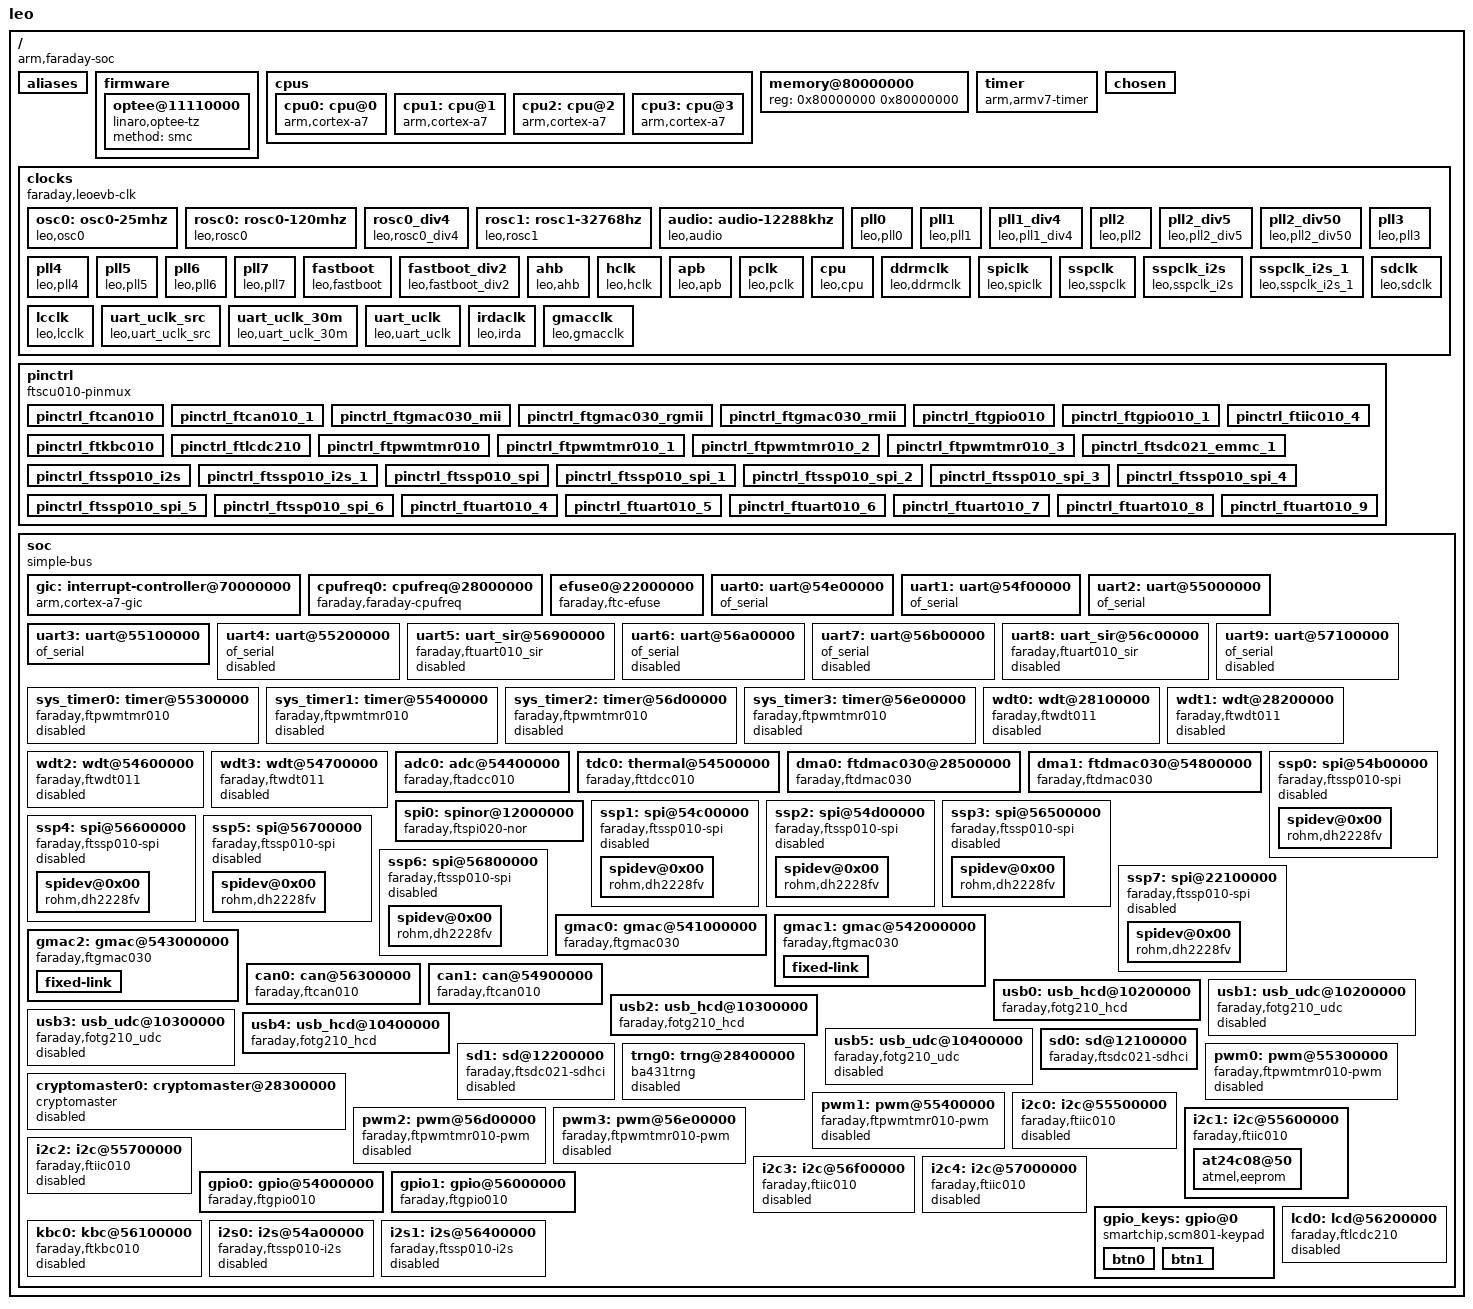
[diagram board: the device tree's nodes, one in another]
/*
 * Copyright (C) 2018 Faraday, Inc. (www.faraday-tech.com)
 *
 * This program is free software; you can redistribute it and/or modify
 * it under the terms of the GNU General Public License version 2 as
 * published by the Free Software Foundation.
 */
 
 /dts-v1/;
 
#include <dt-bindings/interrupt-controller/arm-gic.h>
#include <dt-bindings/input/input.h>
#include <dt-bindings/gpio/gpio.h>
#include <dt-bindings/pinctrl/pinctrl-leo.h>
#include <dt-bindings/thermal/thermal.h>
#include <dt-bindings/scu/scu-leo.h>
 
/ {
	model = "leo";
	compatible = "arm,faraday-soc";
	#address-cells = <1>;
	#size-cells = <1>;
	interrupt-parent = <&gic>;
	
	aliases {
		serial0 = &uart0;
		serial1 = &uart1;
		serial2 = &uart2;
		serial3 = &uart3;
		serial4 = &uart4;
		serial5 = &uart5;
		serial6 = &uart6;
		serial7 = &uart7;
		serial8 = &uart8;
		serial9 = &uart9;
		dmac030_0 = &dma0;
		dmac030_1 = &dma1;
	};
	
	firmware {
		optee@11110000{
		compatible = "linaro,optee-tz";
		method = "smc";
		};
	};
/*
	psci {
		compatible	= "arm,psci";
		method		= "smc";
		cpu_suspend	= <0x84000001>;
		cpu_off		= <0x84000002>;
		cpu_on		= <0x84000003>;
	};
*/
	cpus {
		#address-cells = <1>;
		#size-cells = <0>;
		
		cpu0: cpu@0 {
			compatible = "arm,cortex-a7";
			device_type = "cpu";
			clock-frequency = <800000000>;
			reg = <0x0>;
			/*enable-method = "psci";*/
		};
		cpu1: cpu@1 {
			compatible = "arm,cortex-a7";
			device_type = "cpu";
			clock-frequency = <800000000>;
			reg = <0x1>;
			/*enable-method = "psci";*/
		};
		cpu2: cpu@2 {
			compatible = "arm,cortex-a7";
			device_type = "cpu";
			clock-frequency = <800000000>;
			reg = <0x2>;
			/*enable-method = "psci";*/
		};
		cpu3: cpu@3 {
			compatible = "arm,cortex-a7";
			device_type = "cpu";
			clock-frequency = <800000000>;
			reg = <0x3>;
			/*enable-method = "psci";*/
		};
	};
	
	memory@80000000 {
		device_type = "memory";
		reg = <0x80000000 0x80000000>;
	};
	
	timer {
		compatible = "arm,armv7-timer";
		clock-frequency = <800000000>;  /* kernel default cpu frequency */
		interrupts = <GIC_PPI 13 (GIC_CPU_MASK_SIMPLE(4) | IRQ_TYPE_LEVEL_LOW)>,
		             <GIC_PPI 14 (GIC_CPU_MASK_SIMPLE(4) | IRQ_TYPE_LEVEL_LOW)>,
		             <GIC_PPI 11 (GIC_CPU_MASK_SIMPLE(4) | IRQ_TYPE_LEVEL_LOW)>,
		             <GIC_PPI 10 (GIC_CPU_MASK_SIMPLE(4) | IRQ_TYPE_LEVEL_LOW)>;
		arm,cpu-registers-not-fw-configured;
		clocks = <&cpu>;
		clock-names = "cpu";
		status = "okay";
	};
	
	chosen {
		bootargs = "mem=2048M console=ttyS0,115200 earlycon=uart8250,mmio32,0x54e00000 root=/dev/mmcblk0p2 rw init=/sbin/init rootfstype=ext4";
#if 0
                bootargs = "mem=2048M console=ttyS0,115200 earlycon=uart8250,mmio32,0x54e00000 root=/dev/mmcblk0p2 rw init=/linuxrc rootfstype=ext4";
               bootargs = "root=/dev/nfs   nfsroot=192.168.0.2:/home/niubin/rootfs,vers=3 ip=192.168.0.80:192.168.0.2:192.168.0.1:255.255.255.0::eth0:off init=/linuxrc mem=2048M console=ttyS0,115200 earlycon=uart8250,mmio32,0x54e00000";
#endif
	};
	
	clocks {
		compatible = "faraday,leoevb-clk";
		
		osc0: osc0-25mhz {
			#clock-cells = <0>;
			compatible = "leo,osc0";
			clock-frequency = <25000000>;
			clock-output-names = "osc0";
		};
		
		rosc0: rosc0-120mhz {
			#clock-cells = <0>;
			compatible = "leo,rosc0";
			clock-frequency = <120000000>;
			clock-output-names = "rosc0";
		};
		
		rosc0_div4: rosc0_div4 {
			#clock-cells = <0>;
			compatible = "leo,rosc0_div4";
			clock-mult = <1>;
			clock-div = <4>;
			clock-output-names = "rosc0_div4";
			clocks = <&rosc0>;
		};
		
		rosc1: rosc1-32768hz {
			#clock-cells = <0>;
			compatible = "leo,rosc1";
			clock-frequency = <32768>;
			clock-output-names = "rosc1";
		};
		
		audio: audio-12288khz {
			#clock-cells = <0>;
			compatible = "leo,audio";
			clock-frequency = <12288000>;
			clock-output-names = "audio";
		};
		
		pll0: pll0 {
			#clock-cells = <0>;
			compatible = "leo,pll0";
			clock-div = <1>;
			clock-output-names = "pll0";
			clocks = <&osc0>;
		};
		
		pll1: pll1 {
			#clock-cells = <0>;
			compatible = "leo,pll1";
			clock-div = <1>;
			clock-output-names = "pll1";
			clocks = <&osc0>;
		};
		
		
		pll1_div4: pll1_div4 {
			#clock-cells = <0>;
			compatible = "leo,pll1_div4";
			clock-mult = <1>;
			clock-div = <4>;
			clock-output-names = "pll1_div4";
			clocks = <&pll1>;
		};
		
		pll2: pll2 {
			#clock-cells = <0>;
			compatible = "leo,pll2";
			clock-div = <1>;
			clock-output-names = "pll2";
			clocks = <&osc0>;
		};
		
		pll2_div5: pll2_div5 {
			#clock-cells = <0>;
			compatible = "leo,pll2_div5";
			clock-mult = <1>;
			clock-div = <5>;
			clock-output-names = "pll2_div5";
			clocks = <&pll2>;
		};
		
		pll2_div50: pll2_div50 {
			#clock-cells = <0>;
			compatible = "leo,pll2_div50";
			clock-mult = <1>;
			clock-div = <50>;
			clock-output-names = "pll2_div50";
			clocks = <&pll2>;
		};
		
		pll3: pll3 {
			#clock-cells = <0>;
			compatible = "leo,pll3";
			clock-div = <16>;
			clock-output-names = "pll3";
			clocks = <&pll2_div50>;
		};
		
		pll4: pll4 {
			#clock-cells = <0>;
			compatible = "leo,pll4";
			clock-div = <2>;
			clock-output-names = "pll4";
			clocks = <&osc0>;
		};
		
		pll5: pll5 {
			#clock-cells = <0>;
			compatible = "leo,pll5";
			clock-div = <8>;
			clock-output-names = "pll5";
			clocks = <&pll2_div50>;
		};
		
		pll6: pll6 {
			#clock-cells = <0>;
			compatible = "leo,pll6";
			clock-div = <1>;
			clock-output-names = "pll6";
			clocks = <&osc0>;
		};
		
		pll7: pll7 {
			#clock-cells = <0>;
			compatible = "leo,pll7";
			clock-div = <2>;
			clock-output-names = "pll7";
			clocks = <&osc0>;
		};
		
		fastboot: fastboot {
			#clock-cells = <0>;
			compatible = "leo,fastboot";
			clock-output-names = "fastboot";
			clocks = <&rosc0>, <&osc0>;
		};
		
		fastboot_div2: fastboot_div2 {
			#clock-cells = <0>;
			compatible = "leo,fastboot_div2";
			clock-output-names = "fastboot_div2";
			clock-mult = <1>;
			clock-div = <2>;
			clocks = <&fastboot>;
		};
		
		ahb: ahb {
			#clock-cells = <0>;
			compatible = "leo,ahb";
			clock-mult = <1>;
			clock-div = <4>;
			clock-output-names = "AHB";
			clocks = <&pll1>, <&fastboot_div2>;
		};
		
		hclk: hclk {
			#clock-cells = <0>;
			compatible = "leo,hclk";
			clock-mult = <1>;
			clock-div = <4>;
			clock-output-names = "hclk";
			clocks = <&pll1>, <&fastboot_div2>;
		};
		
		apb: apb {
			#clock-cells = <0>;
			compatible = "leo,apb";
			clock-mult = <1>;
			clock-div = <8>;
			clock-output-names = "APB";
			clocks = <&fastboot>, <&pll6>;
		};
		
		pclk: pclk {
			#clock-cells = <0>;
			compatible = "leo,pclk";
			clock-mult = <1>;
			clock-div = <8>;
			clock-output-names = "pclk";
			clocks = <&fastboot>, <&pll6>;
		};
		
		cpu: cpu {
			#clock-cells = <0>;
			compatible = "leo,cpu";
			mux-reg = <0x30>;
			mux-shift = <6>;
			mux-mask = <1>;
			div-reg = <0x30>;
			div-shift = <4>;
			div-width = <3>;
			clock-output-names = "cpu";
			clocks = <&pll0>, <&fastboot>;
		};
		
		ddrmclk: ddrmclk {
			#clock-cells = <0>;
			compatible = "leo,ddrmclk";
			clock-mult = <1>;
			clock-div = <1>;
			clock-output-names = "ddrmclk";
			clocks = <&pll4>;
		};
		
		spiclk: spiclk {
			#clock-cells = <0>;
			compatible = "leo,spiclk";
			clock-output-names = "spiclk";
			clocks = <&fastboot>, <&pll1>;
		};
		
		sspclk: sspclk {
			#clock-cells = <0>;
			compatible = "leo,sspclk";
			clock-output-names = "sspclk";
			clocks = <&fastboot>, <&pll1>;
		};
		
		sspclk_i2s: sspclk_i2s {
			#clock-cells = <0>;
			compatible = "leo,sspclk_i2s";
			clock-output-names = "sspclk_i2s";
			clocks = <&sspclk>, <&audio>;
		};
		
		sspclk_i2s_1: sspclk_i2s_1 {
			#clock-cells = <0>;
			compatible = "leo,sspclk_i2s_1";
			clock-output-names = "sspclk_i2s_1";
			clocks = <&sspclk>, <&audio>;
		};
		
		sdclk: sdclk {
			#clock-cells = <0>;
			compatible = "leo,sdclk";
			clock-output-names = "sdclk";
			clocks = <&fastboot_div2>, <&pll7>;
		};
		
		lcclk: lcclk {
			#clock-cells = <0>;
			compatible = "leo,lcclk";
			clock-output-names = "lcclk";
			clock-mult = <1>;
			clock-div = <2>;
			clocks = <&pll5>;
		};
		
		uart_uclk_src: uart_uclk_src {
			#clock-cells = <0>;
			compatible = "leo,uart_uclk_src";
			clock-mult = <100>;
			clock-div = <425>;
			clock-output-names = "uart_uclk_src";
			clocks = <&pll1_div4>;
		};
		
		uart_uclk_30m: uart_uclk_30m {
			#clock-cells = <0>;
			compatible = "leo,uart_uclk_30m";
			clock-mult = <1>;
			clock-output-names = "uart_uclk_30m";
			clocks = <&rosc0_div4>, <&uart_uclk_src>;
		};
		
		uart_uclk: uart_uclk {
			#clock-cells = <0>;
			compatible = "leo,uart_uclk";
			clock-mult = <1>;
			clock-output-names = "uart_uclk";
			clocks = <&uart_uclk_30m>, <&pll2_div5>;
		};
		
		irdaclk: irdaclk {
			#clock-cells = <0>;
			compatible = "leo,irda";
			clock-mult = <1>;
			clock-div = <5>;
			clock-output-names = "irda";
			clocks = <&pll2>;
		};
		
		gmacclk: gmacclk {
			#clock-cells = <0>;
			compatible = "leo,gmacclk";
			clock-mult = <1>;
			clock-div = <20>;
			clock-output-names = "gmacclk";
			clocks = <&pll1>;
		};
	};


	pinctrl {
		compatible = "ftscu010-pinmux", "pinctrl-leo";
		reg = <0x28000000 0xA000>;

		scu010,modex = <
			LEO_Mode_X_GPIO0_26
			LEO_Mode_X_GPIO0_25
#if 0
			LEO_Mode_X_GPIO0_24   
#endif 
			LEO_Mode_X_GPIO0_23
			LEO_Mode_X_GPIO0_22
#if 0
			LEO_Mode_X_GPIO0_21
#endif
			LEO_Mode_X_GPIO0_20
			LEO_Mode_X_GPIO0_19
#if 0
			LEO_Mode_X_GPIO0_18
			LEO_Mode_X_GPIO0_17
#endif
			LEO_Mode_X_GPIO0_3
			LEO_Mode_X_GPIO0_2
		>;
		
		pinctrl_ftcan010: pinctrl_ftcan010 {
			scu010,function = <LEO_MUX_FTCAN010>;
			scu010,pins = <
			#if 0
				LEO_PIN_X_LC_PCLK
				LEO_PIN_X_LC_VS
			#elif 0
				LEO_PIN_X_RMII0_TXD_0
				LEO_PIN_X_RMII0_TXD_1
			#else
				LEO_PIN_X_UART5_RX
				LEO_PIN_X_UART5_TX
			#endif
			>;
		};
		
		pinctrl_ftcan010_1: pinctrl_ftcan010_1 {
			scu010,function = <LEO_MUX_FTCAN010_1>;
			scu010,pins = <
			#if 0
				LEO_PIN_X_LC_DE
				LEO_PIN_X_LC_HS
			#elif 0
				LEO_PIN_X_RMII0_RX_CRSDV
				LEO_PIN_X_RMII0_TX_EN
			#else
				LEO_PIN_X_UART8_RX
				LEO_PIN_X_UART8_TX
			#endif
			>;
		};
		
		pinctrl_ftgmac030_mii: pinctrl_ftgmac030_mii {
			scu010,function = <LEO_MUX_FTGMAC030_MII>;
			scu010,pins = <
				LEO_PIN_X_MII_COL
				LEO_PIN_X_MII_CRS
				LEO_PIN_X_MII_MDC
				LEO_PIN_X_MII_MDIO
				LEO_PIN_X_MII_RXD_0
				LEO_PIN_X_MII_RXD_1
				LEO_PIN_X_MII_RXD_2
				LEO_PIN_X_MII_RXD_3
				LEO_PIN_X_MII_RX_CK
				LEO_PIN_X_MII_RX_DV
				LEO_PIN_X_MII_RX_ER
				LEO_PIN_X_MII_TXD_0
				LEO_PIN_X_MII_TXD_1
				LEO_PIN_X_MII_TXD_2
				LEO_PIN_X_MII_TXD_3
				LEO_PIN_X_MII_TX_CK
				LEO_PIN_X_MII_TX_EN
				LEO_PIN_X_MII_TX_ER
			>;
		};
		
		pinctrl_ftgmac030_rgmii: pinctrl_ftgmac030_rgmii {
			scu010,function = <LEO_MUX_FTGMAC030_RGMII>;
			scu010,pins = <
				LEO_PIN_X_RGMII_GTX_CK
				LEO_PIN_X_RGMII_MDC
				LEO_PIN_X_RGMII_MDIO
				LEO_PIN_X_RGMII_RXCTL
				LEO_PIN_X_RGMII_RXD_0
				LEO_PIN_X_RGMII_RXD_1
				LEO_PIN_X_RGMII_RXD_2
				LEO_PIN_X_RGMII_RXD_3
				LEO_PIN_X_RGMII_RX_CK
				LEO_PIN_X_RGMII_TXCTL
				LEO_PIN_X_RGMII_TXD_0
				LEO_PIN_X_RGMII_TXD_1
				LEO_PIN_X_RGMII_TXD_2
				LEO_PIN_X_RGMII_TXD_3
			>;
		};
		
		pinctrl_ftgmac030_rmii: pinctrl_ftgmac030_rmii {
			scu010,function = <LEO_MUX_FTGMAC030_RMII>;
			scu010,pins = <
				LEO_PIN_X_RMII0_MDC
				LEO_PIN_X_RMII0_MDIO
				LEO_PIN_X_RMII0_REF_CLK
				LEO_PIN_X_RMII0_RXD_0
				LEO_PIN_X_RMII0_RXD_1
				LEO_PIN_X_RMII0_RX_CRSDV
				LEO_PIN_X_RMII0_RX_ER
				LEO_PIN_X_RMII0_TXD_0
				LEO_PIN_X_RMII0_TXD_1
				LEO_PIN_X_RMII0_TX_EN
			>;
		};
		
		pinctrl_ftgpio010: pinctrl_ftgpio010 {
			scu010,schmitt-trigger;
			scu010,function = <LEO_MUX_FTGPIO010>;
			scu010,pins = <
				LEO_PIN_X_LC_PCLK        //GPIO0[0] - Mode5 / Mode7
				//LEO_PIN_X_UART5_TX       //GPIO0[0] - Mode3 / GPIO0[2] - ModeX
				//LEO_PIN_X_UART5_RX       //GPIO0[1] - Mode3 / GPIO0[3] - ModeX   
				//LEO_PIN_X_LC_VS          //GPIO0[1] - Mode5 / Mode7
				//LEO_PIN_X_LC_HS          //GPIO0[2] - Mode5 / Mode7
				//LEO_PIN_X_LC_DE          //GPIO0[3] - Mode5 / Mode7
				//LEO_PIN_X_LC_DATA_0      //GPIO0[4] - Mode5 / Mode7
				//LEO_PIN_X_LC_DATA_1      //GPIO0[5] - Mode5 / Mode7
				LEO_PIN_X_LC_DATA_2      //GPIO0[6] - Mode5 / Mode7
				//LEO_PIN_X_LC_DATA_3      //GPIO0[7] - Mode5 / Mode7
				//LEO_PIN_X_LC_DATA_4      //GPIO0[8] - Mode5 / Mode7
				//LEO_PIN_X_LC_DATA_5      //GPIO0[9] - Mode5 / Mode7 / GPIO0[21] - ModeX
				//LEO_PIN_X_UART8_TX       //GPIO0[9] - Mode3  
				//LEO_PIN_X_MII_RX_CK      //GPIO0[9] - Mode1 / Mode3 / Mode4
				//LEO_PIN_X_LC_DATA_6      //GPIO0[10] - Mode5 / Mode7 / GPIO0[17] - ModeX
				//LEO_PIN_X_MII_RXD_2      //GPIO0[10] - Mode1 / Mode3 / Mode4
				//LEO_PIN_X_UART8_RX       //GPIO0[10] - Mode3
				//LEO_PIN_X_MII_RXD_3      //GPIO0[11] - Mode1 / Mode3 / Mode4) 
				//LEO_PIN_X_UART8_RX_h     //GPIO0[11] - Mode3 
				//LEO_PIN_X_LC_DATA_7      //GPIO0[11] - Mode5 / Mode7
				//LEO_PIN_X_LC_DATA_8      //GPIO0[12] - Mode5 / Mode7
				//LEO_PIN_X_MII_TX_CK      //GPIO0[12] - Mode1 / Mode3 /Mode4 
				//LEO_PIN_X_LC_DATA_9      //GPIO0[13] - Mode5 / Mode7
				//LEO_PIN_X_MII_TX_ER      //GPIO0[13] - Mode1 / Mode3 / Mode4
				//LEO_PIN_X_LC_DATA_10     //GPIO0[14] - Mode5 / Mode7
				//LEO_PIN_X_MII_TXD_2      //GPIO0[14] - Mode1 / Mode3 / Mode4
				//LEO_PIN_X_MII_TXD_3      //GPIO0[15] - Mode1 / Mode3 / Mode4
				//LEO_PIN_X_LC_DATA_11     //GPIO0[15] - Mode5 / Mode7
				//LEO_PIN_X_LC_DATA_12     //GPIO0[16] - Mode5 / Mode7
				//LEO_PIN_X_MII_CRS        //GPIO0[16] - Mode1 / Mode3 / Mode4
				//LEO_PIN_X_LC_DATA_13     //GPIO0[17] - Mode5 / Mode7
				//LEO_PIN_X_MII_COL        //GPIO0[17] - Mode1 / Mode3 / Mode4
				//LEO_PIN_X_LC_DATA_14     //GPIO0[18] - Mode5 / Mode7
				//LEO_PIN_X_I2S0_TXD       //GPIO0[18] - ModeX 
				//LEO_PIN_X_LC_DATA_15     //GPIO0[19] - Mode5 / Mode7
				//LEO_PIN_X_UART2_NRTS     //GPIO0[19] - ModeX 
				//LEO_PIN_X_LC_DATA_16     //GPIO0[20] - Mode5 / Mode7
				//LEO_PIN_X_UART2_NCTS     //GPIO0[20] - ModeX
				//LEO_PIN_X_LC_DATA_17     //GPIO0[21] - Mode5 / Mode7
				//LEO_PIN_X_LC_DATA_18     //GPIO0[22] - Mode5 / Mode7
				//LEO_PIN_X_I2S0_RXD       //GPIO0[22] - ModeX /GPIO1[12] - Mode2
				//LEO_PIN_X_I2S0_SCLK      //GPIO0[23] - ModeX /GPIO1[13] - Mode2
				//LEO_PIN_X_LC_DATA_19     //GPIO0[23] - Mode5 / Mode7
				//LEO_PIN_X_LC_DATA_20     //GPIO0[24] - Mode5 / Mode7
				//LEO_PIN_X_MII_TX_EN      //GPIO0[24] - Mode7
				//LEO_PIN_X_LC_DATA_21     //GPIO0[25] - Mode5 / Mode7
				//LEO_PIN_X_I2S0_FS        //GPIO0[25] - ModeX
				//LEO_PIN_X_RMII0_RXD_1    //GPIO0[26] - ModeX 
				//LEO_PIN_X_LC_DATA_22     //GPIO0[26] - Mode5 / Mode7
				LEO_PIN_X_LC_DATA_23     //GPIO0[27] - Mode5 / Mode7
				LEO_PIN_X_I2S_MCLK       //GPIO0[28] - Mode2 / Mode6 / Mode7
				//LEO_PIN_X_MII_MDC        //GPIO0[31] - Mode7
				LEO_PIN_X_LC_DE         //gpio0[3]
			>;
		};
		
		pinctrl_ftgpio010_1: pinctrl_ftgpio010_1 {
			scu010,schmitt-trigger;
			scu010,function = <LEO_MUX_FTGPIO010_1>;
			scu010,pins = <
				//LEO_PIN_X_MII_MDIO       //GPIO1[0] - Mode7 / GPIO1[26] - Mode1 / Mode3
				//LEO_PIN_X_EMMC1_D7       //GPIO1[0] - Mode1 / Mode3 / Mode4 / Mode5 / Mode7
				//LEO_PIN_X_MII_RX_CK      //GPIO1[1] - Mode7
				//LEO_PIN_X_EMMC1_D6       //GPIO1[1] - Mode1 / Mode3 / Mode4 / Mode5 / Mode7
				//LEO_PIN_X_EMMC1_D5       //GPIO1[2] - Mode1 / Mode3 / Mode4 /Mode5 / Mode7
				//LEO_PIN_X_MII_RXD_2      //GPIO1[2] - Mode7
				//LEO_PIN_X_MII_RXD_3      //GPIO1[3] - Mode7
				//LEO_PIN_X_EMMC1_D4       //GPIO1[3] - Mode1 / Mode3 / Mode4 / Mode5 / Mode7
				//LEO_PIN_X_EMMC1_D3       //GPIO1[4] - Mode1 / Mode3 / Mode4 / Mode5 / Mode7
				//LEO_PIN_X_MII_TX_CK      //GPIO1[4] - Mode7
				//LEO_PIN_X_RMII0_TXD_0    //GPIO1[5] - Mode7
				//LEO_PIN_X_EMMC1_D2       //GPIO1[5] - Mode1 / Mode3 / Mode4 / Mode5 / Mode7
				//LEO_PIN_X_EMMC1_D1       //GPIO1[6] - Mode1 / Mode3 / Mode4 / Mode5 / Mode7
				//LEO_PIN_X_RMII0_TXD_1    //GPIO1[6] - Mode7
				//LEO_PIN_X_EMMC1_D0       //GPIO1[7] - Mode1 / Mode3 / Mode4 / Mode5 / Mode7
				//LEO_PIN_X_RMII0_TX_EN    //GPIO1[7] - Mode7
				//LEO_PIN_X_EMMC1_RSTN     //GPIO1[8] - Mode1 / Mode3 / Mode4 / Mode5 / Mode7
				//LEO_PIN_X_RMII0_RX_CRSDV //GPIO1[8] - Mode7
				//LEO_PIN_X_EMMC1_CMD      //GPIO1[9] - Mode1 / Mode3 / Mode4 / Mode5 / Mode7
				//LEO_PIN_X_RMII0_RX_ER    //GPIO1[9] - Mode7
				//LEO_PIN_X_RMII0_RXD_0    //GPIO1[10] - Mode7
				//LEO_PIN_X_RMII0_RXD_1    //GPIO1[11] - Mode3 / Mode5 / Mode7
				//LEO_PIN_X_I2S0_FS        //GPIO1[11] - Mode2
				//LEO_PIN_X_I2S0_RXD       //GPIO1[12] - Mode2
				//LEO_PIN_X_RGMII_GTX_CK   //GPIO1[12] - Mode3 / Mode5 / Mode7
				//LEO_PIN_X_UART8_TX       //GPIO1[12] - Mode6
				//LEO_PIN_X_I2S0_SCLK      //GPIO1[13] - Mode2
				//LEO_PIN_X_UART8_RX       //GPIO1[13] - Mode6
				//LEO_PIN_X_RGMII_MDC      //GPIO1[13] - Mode3 / Mode5 / Mode7 / GPIO1[25] - Mode2
				//LEO_PIN_X_UART8_RX_h     //GPIO1[14] - Mode6
				//LEO_PIN_X_RMII0_MDIO      //GPIO1[14] - Mode3 / Mode5 / Mode7
				//LEO_PIN_X_MII_TX_ER      //GPIO1[15] - Mode7
				//LEO_PIN_X_MII_TXD_2      //GPIO1[16] - Mode7
				//LEO_PIN_X_MII_TXD_3      //GPIO1[17] - Mode7
				//LEO_PIN_X_MII_CRS        //GPIO1[18] - Mode7
				//LEO_PIN_X_MII_COL        //GPIO1[19] - Mode7
				//LEO_PIN_X_MII_TXD_0      //GPIO1[23] - Mode7
				//LEO_PIN_X_RGMII_MDC      //GPIO1[23] - Mode1 / Mode2 / Mode4
				//LEO_PIN_X_RGMII_MDIO     //GPIO1[24] - Mode1 / Mode2 / Mode4
				//LEO_PIN_X_MII_TXD_1      //GPIO1[24] - Mode7
				//LEO_PIN_X_MII_TX_EN      //GPIO1[25] - ModeX
				//LEO_PIN_X_MII_MDC        //GPIO1[25] - Mode1 / Mode3
				//LEO_PIN_X_RMII0_MDC      //GPIO1[25] - Mode2 / GPIO1[13] - Mode3 / Mode5 / Mode7
				//LEO_PIN_X_MII_RX_DV      //GPIO1[26] - Mode7
				//LEO_PIN_X_MII_RX_ER      //GPIO1[27] - Mode7
				//LEO_PIN_X_MII_RXD_0      //GPIO1[28] - Mode7
				//LEO_PIN_X_MII_RXD_1      //GPIO1[29] - Mode7
			>;
		};
		
		pinctrl_ftiic010_4: pinctrl_ftiic010_4 {
			scu010,function = <LEO_MUX_FTIIC010_4>;
			scu010,pins = <
			#if 1
				LEO_PIN_X_EMMC1_D2
				LEO_PIN_X_EMMC1_D3
			#else
				LEO_PIN_X_LC_DATA_8
				LEO_PIN_X_LC_DATA_9
			#endif
			>;
		};
		
		pinctrl_ftkbc010: pinctrl_ftkbc010 {
			scu010,function = <LEO_MUX_FTKBC010>;
			scu010,pins = <
			#if 0
				LEO_PIN_X_I2S0_FS			//CODE_X0
				LEO_PIN_X_I2S0_RXD 			//CODE_X1
				LEO_PIN_X_I2S0_SCLK			//CODE_X2
				LEO_PIN_X_I2S0_TXD 			//CODE_X3
			#else
				LEO_PIN_X_RGMII_RX_CK		//CODE_X0
				LEO_PIN_X_RGMII_RXD_0		//CODE_X1
				LEO_PIN_X_RGMII_RXD_1		//CODE_X2
				LEO_PIN_X_RGMII_RXD_2		//CODE_X3
			#endif
				LEO_PIN_X_RGMII_RXD_3		//CODE_X4
				LEO_PIN_X_RGMII_RXCTL		//CODE_X5
				LEO_PIN_X_RGMII_GTX_CK 		//CODE_X6
				LEO_PIN_X_RGMII_TXCTL		//CODE_X7

			#if 0
				LEO_PIN_X_MII_TXD_0			//CODE_Y0
				LEO_PIN_X_MII_TXD_1			//CODE_Y1
				LEO_PIN_X_MII_TX_EN			//CODE_Y2
				LEO_PIN_X_MII_RX_DV			//CODE_Y3
				LEO_PIN_X_MII_RX_ER			//CODE_Y4
				LEO_PIN_X_MII_RXD_0			//CODE_Y5
				LEO_PIN_X_MII_RXD_1			//CODE_Y6
			#elif 1
				LEO_PIN_X_RMII0_TXD_0		//CODE_Y0
				LEO_PIN_X_RMII0_TXD_1		//CODE_Y1
				LEO_PIN_X_RMII0_TX_EN		//CODE_Y2
				LEO_PIN_X_RMII0_RX_CRSDV	//CODE_Y3
				LEO_PIN_X_RMII0_RX_ER		//CODE_Y4
				LEO_PIN_X_RMII0_RXD_0		//CODE_Y5
				LEO_PIN_X_RMII0_RXD_1		//CODE_Y6
			#else
				LEO_PIN_X_UART5_TX 			//CODE_Y0
				LEO_PIN_X_UART5_RX 			//CODE_Y1
				LEO_PIN_X_UART5_RX_h		//CODE_Y2
				LEO_PIN_X_UART6_TX 			//CODE_Y3
				LEO_PIN_X_UART6_RX 			//CODE_Y4
				LEO_PIN_X_UART9_TX 			//CODE_Y5
				LEO_PIN_X_UART7_TX 			//CODE_Y6
			#endif

			#if 1
				LEO_PIN_X_RMII0_REF_CLK		//CODE_Y7
			#else
				LEO_PIN_X_UART7_RX	 		//CODE_Y7
			#endif
			>;
		};
		
		pinctrl_ftlcdc210: pinctrl_ftlcdc210 {
			scu010,function = <LEO_MUX_FTLCDC210>;
			scu010,pins = <
				LEO_PIN_X_LC_DATA_0
				LEO_PIN_X_LC_DATA_1
				LEO_PIN_X_LC_DATA_10
				LEO_PIN_X_LC_DATA_11
				LEO_PIN_X_LC_DATA_12
				LEO_PIN_X_LC_DATA_13
				LEO_PIN_X_LC_DATA_14
				LEO_PIN_X_LC_DATA_15
				LEO_PIN_X_LC_DATA_16
				LEO_PIN_X_LC_DATA_17
				LEO_PIN_X_LC_DATA_18
				LEO_PIN_X_LC_DATA_19
				LEO_PIN_X_LC_DATA_2
				LEO_PIN_X_LC_DATA_20
				LEO_PIN_X_LC_DATA_21
				LEO_PIN_X_LC_DATA_22
				LEO_PIN_X_LC_DATA_23
				LEO_PIN_X_LC_DATA_3
				LEO_PIN_X_LC_DATA_4
				LEO_PIN_X_LC_DATA_5
				LEO_PIN_X_LC_DATA_6
				LEO_PIN_X_LC_DATA_7
				LEO_PIN_X_LC_DATA_8
				LEO_PIN_X_LC_DATA_9
				LEO_PIN_X_LC_DE
				LEO_PIN_X_LC_HS
				LEO_PIN_X_LC_PCLK
				LEO_PIN_X_LC_VS
			>;
		};
		
		pinctrl_ftpwmtmr010: pinctrl_ftpwmtmr010 {
			scu010,function = <LEO_MUX_FTPWMTMR010>;
			scu010,pins = <
				LEO_PIN_X_EMMC1_CLK
				LEO_PIN_X_I2S0_FS
				LEO_PIN_X_I2S0_RXD
				LEO_PIN_X_I2S0_SCLK
				LEO_PIN_X_LC_DATA_0
				LEO_PIN_X_LC_DATA_1
				LEO_PIN_X_LC_DATA_2
				LEO_PIN_X_LC_DATA_3
				LEO_PIN_X_MII_MDC
				LEO_PIN_X_MII_MDIO
				LEO_PIN_X_RGMII_TXD_0
				LEO_PIN_X_RGMII_TXD_1
				LEO_PIN_X_RMII0_MDIO
				LEO_PIN_X_UART5_RX_h
				LEO_PIN_X_UART8_RX_h
			>;
		};
		
		pinctrl_ftpwmtmr010_1: pinctrl_ftpwmtmr010_1 {
			scu010,function = <LEO_MUX_FTPWMTMR010_1>;
			scu010,pins = <
				LEO_PIN_X_I2S0_TXD
				LEO_PIN_X_RGMII_MDC
				//LEO_PIN_X_RGMII_MDIO
				LEO_PIN_X_RGMII_TXD_2
				LEO_PIN_X_RGMII_TXD_3
			>;
		};
		
		pinctrl_ftpwmtmr010_2: pinctrl_ftpwmtmr010_2 {
			scu010,function = <LEO_MUX_FTPWMTMR010_2>;
			scu010,pins = <
				LEO_PIN_X_RMII0_RX_CRSDV
				LEO_PIN_X_RMII0_TXD_0
				LEO_PIN_X_RMII0_TXD_1
				LEO_PIN_X_RMII0_TX_EN
			>;
		};
		
		pinctrl_ftpwmtmr010_3: pinctrl_ftpwmtmr010_3 {
			scu010,function = <LEO_MUX_FTPWMTMR010_3>;
			scu010,pins = <
				LEO_PIN_X_RMII0_RXD_0
				LEO_PIN_X_RMII0_RX_ER
			>;
		};
		
		pinctrl_ftsdc021_emmc_1: pinctrl_ftsdc021_emmc_1 {
			scu010,function = <LEO_MUX_FTSDC021_EMMC_1>;
			scu010,pins = <
				LEO_PIN_X_EMMC1_CLK
				LEO_PIN_X_EMMC1_CMD
				LEO_PIN_X_EMMC1_D0
				LEO_PIN_X_EMMC1_D1
				LEO_PIN_X_EMMC1_D2
				LEO_PIN_X_EMMC1_D3
				LEO_PIN_X_EMMC1_D4
				LEO_PIN_X_EMMC1_D5
				LEO_PIN_X_EMMC1_D6
				LEO_PIN_X_EMMC1_D7
				LEO_PIN_X_EMMC1_RSTN
			>;
		};
		
		pinctrl_ftssp010_i2s: pinctrl_ftssp010_i2s {
			scu010,function = <LEO_MUX_FTSSP010_I2S>;
			scu010,pins = <
				LEO_PIN_X_I2S_MCLK
				LEO_PIN_X_I2S0_FS
				LEO_PIN_X_I2S0_RXD
				LEO_PIN_X_I2S0_SCLK
				LEO_PIN_X_I2S0_TXD
			>;
		};
		
		pinctrl_ftssp010_i2s_1: pinctrl_ftssp010_i2s_1 {
			scu010,function = <LEO_MUX_FTSSP010_I2S_1>;
			scu010,pins = <
				LEO_PIN_X_I2S_MCLK
			#if 1
				LEO_PIN_X_EMMC1_D4
				LEO_PIN_X_EMMC1_D5
				LEO_PIN_X_EMMC1_D6
				LEO_PIN_X_EMMC1_D7
			#else
				LEO_PIN_X_LC_DATA_4
				LEO_PIN_X_LC_DATA_5
				LEO_PIN_X_LC_DATA_6
				LEO_PIN_X_LC_DATA_7
			#endif
			>;
		};
		
		pinctrl_ftssp010_spi: pinctrl_ftssp010_spi {
			scu010,function = <LEO_MUX_FTSSP010_SPI>;
			scu010,pins = <
				LEO_PIN_X_LC_DATA_12
				LEO_PIN_X_LC_DATA_13
				LEO_PIN_X_SPI_DCX1
			>;
		};
		
		pinctrl_ftssp010_spi_1: pinctrl_ftssp010_spi_1 {
			scu010,function = <LEO_MUX_FTSSP010_SPI_1>;
			scu010,pins = <
				LEO_PIN_X_LC_DATA_14
				LEO_PIN_X_LC_DATA_15
				LEO_PIN_X_SPI_DCX2
			>;
		};
		
		pinctrl_ftssp010_spi_2: pinctrl_ftssp010_spi_2 {
			scu010,function = <LEO_MUX_FTSSP010_SPI_2>;
			scu010,pins = <
				LEO_PIN_X_LC_DATA_16
				LEO_PIN_X_LC_DATA_17
				LEO_PIN_X_SPI_DCX1
			>;
		};
		
		pinctrl_ftssp010_spi_3: pinctrl_ftssp010_spi_3 {
			scu010,function = <LEO_MUX_FTSSP010_SPI_3>;
			scu010,pins = <
				LEO_PIN_X_LC_DATA_18
				LEO_PIN_X_LC_DATA_19
				LEO_PIN_X_SPI_DCX2
			>;
		};
		
		pinctrl_ftssp010_spi_4: pinctrl_ftssp010_spi_4 {
			scu010,function = <LEO_MUX_FTSSP010_SPI_4>;
			scu010,pins = <
				LEO_PIN_X_LC_DATA_20
				LEO_PIN_X_LC_DATA_21
				LEO_PIN_X_LC_DATA_22
				LEO_PIN_X_LC_DATA_23
				LEO_PIN_X_SPI_DCX1
			>;
		};
		
		pinctrl_ftssp010_spi_5: pinctrl_ftssp010_spi_5 {
			scu010,function = <LEO_MUX_FTSSP010_SPI_5>;
			scu010,pins = <
				LEO_PIN_X_SPI_DCX2
			>;
		};
		
		pinctrl_ftssp010_spi_6: pinctrl_ftssp010_spi_6 {
			scu010,function = <LEO_MUX_FTSSP010_SPI_6>;
			scu010,pins = <
				LEO_PIN_X_EMMC1_CMD
				LEO_PIN_X_EMMC1_RSTN
				LEO_PIN_X_SPI_DCX1
			>;
		};
		
		pinctrl_ftuart010_4: pinctrl_ftuart010_4 {
			scu010,function = <LEO_MUX_FTUART010_4>;
			scu010,pins = <
				LEO_PIN_X_EMMC1_D0
				LEO_PIN_X_EMMC1_D1
				LEO_PIN_X_LC_DATA_10
				LEO_PIN_X_LC_DATA_11
			>;
		};
		
		pinctrl_ftuart010_5: pinctrl_ftuart010_5 {
			scu010,function = <LEO_MUX_FTUART010_5>;
			scu010,pins = <
				LEO_PIN_X_UART5_RX
				LEO_PIN_X_UART5_RX_h
				LEO_PIN_X_UART5_TX
			>;
		};
		
		pinctrl_ftuart010_6: pinctrl_ftuart010_6 {
			scu010,function = <LEO_MUX_FTUART010_6>;
			scu010,pins = <
				LEO_PIN_X_UART6_RX
				LEO_PIN_X_UART6_TX
			>;
		};
		
		pinctrl_ftuart010_7: pinctrl_ftuart010_7 {
			scu010,function = <LEO_MUX_FTUART010_7>;
			scu010,pins = <
				LEO_PIN_X_UART7_RX
				LEO_PIN_X_UART7_TX
			>;
		};
		
		pinctrl_ftuart010_8: pinctrl_ftuart010_8 {
			scu010,function = <LEO_MUX_FTUART010_8>;
			scu010,pins = <
				LEO_PIN_X_UART8_RX
				LEO_PIN_X_UART8_RX_h
				LEO_PIN_X_UART8_TX
			>;
		};
		
		pinctrl_ftuart010_9: pinctrl_ftuart010_9 {
			scu010,function = <LEO_MUX_FTUART010_9>;
			scu010,pins = <
				LEO_PIN_X_UART9_RX
				LEO_PIN_X_UART9_TX
			>;
		};
	};
	
	soc {
		#address-cells = <1>;
		#size-cells = <1>;
		compatible = "simple-bus";
		ranges;
		
		gic: interrupt-controller@70000000 {
			compatible = "arm,cortex-a7-gic";
			interrupt-controller;
			#interrupt-cells = <3>;
			reg = <0x70001000 0x1000>,
			      <0x70002000 0x2000>,
			      <0x70004000 0x2000>,
			      <0x70006000 0x2000>;
		};

		cpufreq0: cpufreq@28000000 {
			compatible = "faraday,faraday-cpufreq";
			interrupt-parent = <&gic>;
			reg = <0x28000000 0xA000>,
			      <0x28900000 0x1000>,
			      <0x54e00000 0x1000>;
			reg-names = "sysc", "ddrc", "uart";
			interrupts = <GIC_SPI 0 IRQ_TYPE_LEVEL_HIGH>;
			clocks = <&cpu>;
			clock-names = "cpu";
			operating-points = <
				/* KHz	  uV */
				100000 1100000
				200000 1100000
				400000 1100000
				800000 1100000
			>;
			status = "okay";
		};

		efuse0@22000000 {
	                compatible = "faraday,ftc-efuse";
        	        interrupt-parent = <&gic>;
                	reg = <0x22000000 0x10000>;
	                efuse-size = <512>;   /* 4096 bits */
        	        status = "okay";
        	};

		uart0: uart@54e00000 {
			compatible = "of_serial", "ns16550a";
			interrupt-parent = <&gic>;
			clock-frequency = <58823529>;
			reg = <0x54e00000 0x1000>;
			reg-offset = <0>;
			reg-shift = <2>;
			reg-io-width = <4>;
			no-loopback-test;
			interrupts = <GIC_SPI 45 IRQ_TYPE_LEVEL_HIGH>;
			serial = <0>;
			status = "okay";
		};
		
		uart1: uart@54f00000 {
			compatible = "of_serial", "ns16550a";
			interrupt-parent = <&gic>;
			clock-frequency = <58823529>;
			reg = <0x54f00000 0x1000>;
			reg-offset = <0>;
			reg-shift = <2>;
			reg-io-width = <4>;
			no-loopback-test;
			interrupts = <GIC_SPI 47 IRQ_TYPE_LEVEL_HIGH>;
			serial = <1>;
			status = "okay";
		};
		
		uart2: uart@55000000 {
			compatible = "of_serial", "ns16550a";
			interrupt-parent = <&gic>;
			clock-frequency = <58823529>;
			reg = <0x55000000 0x1000>;
			reg-offset = <0>;
			reg-shift = <2>;
			reg-io-width = <4>;
			no-loopback-test;
			interrupts = <GIC_SPI 49 IRQ_TYPE_LEVEL_HIGH>;
			serial = <2>;
			rs485-dir-gpios = <19>;
			status = "okay";
		};
		
		uart3: uart@55100000 {
			compatible = "of_serial", "ns16550a";
			interrupt-parent = <&gic>;
			clock-frequency = <58823529>;
			reg = <0x55100000 0x1000>;
			reg-offset = <0>;
			reg-shift = <2>;
			reg-io-width = <4>;
			no-loopback-test;
			interrupts = <GIC_SPI 51 IRQ_TYPE_LEVEL_HIGH>;
			serial = <3>;
			rs485-dir-gpios = <20>;
			//led-gpios = <21>;
			status = "okay";
		};
		
		uart4: uart@55200000 {
			compatible = "of_serial", "ns16550a";
			interrupt-parent = <&gic>;
			clock-frequency = <58823529>;
			reg = <0x55200000 0x1000>;
			reg-offset = <0>;
			reg-shift = <2>;
			reg-io-width = <4>;
			no-loopback-test;
			interrupts = <GIC_SPI 53 IRQ_TYPE_LEVEL_HIGH>;
			pinctrl-0 = <&pinctrl_ftuart010_4>;
			pinctrl-names = "sleep";
			serial = <4>;
			status = "disabled";
		};
		
		uart5: uart_sir@56900000 {
			compatible = "faraday,ftuart010_sir";
			interrupt-parent = <&gic>;
			clock-frequency = <58823529>;
			reg = <0x56900000 0x1000>;
			interrupts = <GIC_SPI 55 IRQ_TYPE_LEVEL_HIGH>;
			reg-offset = <0>;
			reg-shift = <2>;
			reg-io-width = <4>;
			no-loopback-test;
			pinctrl-0 = <&pinctrl_ftuart010_5>;
			pinctrl-names = "sleep";
			serial = <5>;
			status = "disabled";
		};
		
		uart6: uart@56a00000 {
			compatible = "of_serial", "ns16550a";
			interrupt-parent = <&gic>;
			clock-frequency = <58823529>;
			reg = <0x56a00000 0x1000>;
			reg-offset = <0>;
			reg-shift = <2>;
			reg-io-width = <4>;
			no-loopback-test;
			interrupts = <GIC_SPI 57 IRQ_TYPE_LEVEL_HIGH>;
			pinctrl-0 = <&pinctrl_ftuart010_6>;
			pinctrl-names = "sleep";
			serial = <6>;
			status = "disabled";
		};
		
		uart7: uart@56b00000 {
			compatible = "of_serial", "ns16550a";
			interrupt-parent = <&gic>;
			clock-frequency = <58823529>;
			reg = <0x56b00000 0x1000>;
			reg-offset = <0>;
			reg-shift = <2>;
			reg-io-width = <4>;
			no-loopback-test;
			interrupts = <GIC_SPI 59 IRQ_TYPE_LEVEL_HIGH>;
			pinctrl-0 = <&pinctrl_ftuart010_7>;
			pinctrl-names = "sleep";
			serial = <7>;
			status = "disabled";
		};
		
		uart8: uart_sir@56c00000 {
			compatible = "faraday,ftuart010_sir";
			interrupt-parent = <&gic>;
			reg = <0x56c00000 0x1000>;
			interrupts = <GIC_SPI 61 IRQ_TYPE_LEVEL_HIGH>;
			baud = <115200>;
			clock-names = "irda";
			clocks = <&irdaclk>;
			pinctrl-0 = <&pinctrl_ftuart010_8>;
			pinctrl-names = "default";
			serial = <8>;
			status = "disabled";
		};
		
		uart9: uart@57100000 {
			compatible = "of_serial", "ns16550a";
			interrupt-parent = <&gic>;
			clock-frequency = <58823529>;
			reg = <0x57100000 0x1000>;
			reg-offset = <0>;
			reg-shift = <2>;
			reg-io-width = <4>;
			no-loopback-test;
			interrupts = <GIC_SPI 63 IRQ_TYPE_LEVEL_HIGH>;
			pinctrl-0 = <&pinctrl_ftuart010_9>;
			pinctrl-names = "sleep";
			serial = <9>;
			status = "disabled";
		};
		
		sys_timer0: timer@55300000 {
			compatible = "faraday,ftpwmtmr010";
			interrupt-parent = <&gic>;
			interrupts = <GIC_SPI 20 IRQ_TYPE_LEVEL_HIGH>;
			reg = <0x55300000 0x100>;
			clocks = <&apb>;
			clock-names = "APB";
			pinctrl-0 = <&pinctrl_ftpwmtmr010>;
			pinctrl-names = "sleep";
			status = "disabled";
		};
		
		sys_timer1: timer@55400000 {
			compatible = "faraday,ftpwmtmr010";
			interrupt-parent = <&gic>;
			interrupts = <GIC_SPI 25 IRQ_TYPE_LEVEL_HIGH>;
			reg = <0x55400000 0x100>;
			clocks = <&apb>;
			clock-names = "APB";
			pinctrl-0 = <&pinctrl_ftpwmtmr010_1>;
			pinctrl-names = "sleep";
			status = "disabled";
		};
		
		sys_timer2: timer@56d00000 {
			compatible = "faraday,ftpwmtmr010";
			interrupt-parent = <&gic>;
			interrupts = <GIC_SPI 30 IRQ_TYPE_LEVEL_HIGH>;
			reg = <0x56d00000 0x100>;
			clocks = <&apb>;
			clock-names = "APB";
			pinctrl-0 = <&pinctrl_ftpwmtmr010_2>;
			pinctrl-names = "sleep";
			status = "disabled";
		};
		
		sys_timer3: timer@56e00000 {
			compatible = "faraday,ftpwmtmr010";
			interrupt-parent = <&gic>;
			interrupts = <GIC_SPI 35 IRQ_TYPE_LEVEL_HIGH>;
			reg = <0x56e00000 0x100>;
			clocks = <&apb>;
			clock-names = "APB";
			pinctrl-0 = <&pinctrl_ftpwmtmr010_3>;
			pinctrl-names = "sleep";
			status = "disabled";
		};
		
		wdt0: wdt@28100000 {
			compatible = "faraday,ftwdt011";
			interrupt-parent = <&gic>;
			reg = <0x28100000 0x1000>;
			interrupts = <GIC_SPI 3 IRQ_TYPE_LEVEL_HIGH>;
			clocks = <&rosc1>;
			clock-names = "rosc1";
			status = "disabled";
		};
		
		wdt1: wdt@28200000 {
			compatible = "faraday,ftwdt011";
			interrupt-parent = <&gic>;
			reg = <0x28200000 0x1000>;
			interrupts = <GIC_SPI 4 IRQ_TYPE_LEVEL_HIGH>;
			clocks = <&rosc1>;
			clock-names = "rosc1";
			status = "disabled";
		};
		
		wdt2: wdt@54600000 {
			compatible = "faraday,ftwdt011";
			interrupt-parent = <&gic>;
			reg = <0x54600000 0x1000>;
			interrupts = <GIC_SPI 5 IRQ_TYPE_LEVEL_HIGH>;
			clocks = <&rosc1>;
			clock-names = "rosc1";
			status = "disabled";
		};
		
		wdt3: wdt@54700000 {
			compatible = "faraday,ftwdt011";
			interrupt-parent = <&gic>;
			reg = <0x54700000 0x1000>;
			interrupts = <GIC_SPI 6 IRQ_TYPE_LEVEL_HIGH>;
			clocks = <&rosc1>;
			clock-names = "rosc1";
			status = "disabled";
		};
		
		adc0: adc@54400000 {
			compatible = "faraday,ftadcc010";
			interrupt-parent = <&gic>;
			reg = <0x54400000 0x1000>;
			interrupts = <GIC_SPI 76 IRQ_TYPE_LEVEL_HIGH>;
			status = "okay";
		};
		
		tdc0: thermal@54500000 {
			compatible = "faraday,fttdcc010";
			interrupt-parent = <&gic>;
			reg = <0x54500000 0x1000>;
			interrupts = <GIC_SPI 77 IRQ_TYPE_LEVEL_HIGH>;
			status = "okay";
		};
		
		dma0: ftdmac030@28500000 {
			compatible = "faraday,ftdmac030";
			interrupt-parent = <&gic>;
			dev_id = <0>;
			#dma-cells = <3>;
			reg = <0x28500000 0x1000>;
			interrupts = <GIC_SPI 116 IRQ_TYPE_LEVEL_HIGH>;
			status = "okay";
		};
		
		dma1: ftdmac030@54800000 {
			compatible = "faraday,ftdmac030";
			interrupt-parent = <&gic>;
			dev_id = <1>;
			#dma-cells = <3>;
			reg = <0x54800000 0x1000>;
			interrupts = <GIC_SPI 119 IRQ_TYPE_LEVEL_HIGH>;
			status = "okay";
		};

		spi0: spinor@12000000 {
			compatible = "faraday,ftspi020-nor";
			interrupt-parent = <&gic>;
			dma-req-sel = <0>;
			reg = <0x12000000 0x1000>;
			interrupts = <GIC_SPI 69 IRQ_TYPE_LEVEL_HIGH>;
			clocks = <&spiclk>;
			clock-names = "spiclk";
			status = "okay";
		};


		ssp0: spi@54b00000 {
			compatible = "faraday,ftssp010-spi";
			interrupt-parent = <&gic>;
			reg = <0x54b00000 0x1000>;
			interrupts = <GIC_SPI 12 IRQ_TYPE_LEVEL_HIGH>;
			clocks = <&sspclk>;
			clock-names = "sspclk";
#if 0
			pinctrl-0 = <&pinctrl_ftssp010_spi>;
			pinctrl-names = "sleep";
#endif
			dev_id = <0>;//禁止改动
			status = "disabled";
			
			#address-cells = <1>;
			#size-cells = <0>;
			spidev@0x00 {
				compatible = "rohm,dh2228fv";
				spi-max-frequency = <20000000>;
				reg = <0>;
			};
		};
		
		ssp1: spi@54c00000 {
			compatible = "faraday,ftssp010-spi";
			interrupt-parent = <&gic>;
			reg = <0x54c00000 0x1000>;
			interrupts = <GIC_SPI 13 IRQ_TYPE_LEVEL_HIGH>;
			clocks = <&sspclk>;
			clock-names = "sspclk";
			pinctrl-0 = <&pinctrl_ftssp010_spi_1>;
			pinctrl-names = "sleep";
			dev_id = <1>;//禁止改动
			status = "disabled";
			
			#address-cells = <1>;
			#size-cells = <0>;
			spidev@0x00 {
				compatible = "rohm,dh2228fv";	
				spi-max-frequency = <20000000>;
				reg = <0>;
			};
		};
		
		ssp2: spi@54d00000 {
			compatible = "faraday,ftssp010-spi";
			interrupt-parent = <&gic>;
			reg = <0x54d00000 0x1000>;
			interrupts = <GIC_SPI 14 IRQ_TYPE_LEVEL_HIGH>;
			clocks = <&sspclk>;
			clock-names = "sspclk";
			pinctrl-0 = <&pinctrl_ftssp010_spi_2>;
			pinctrl-names = "sleep";
			dev_id = <2>;
			status = "disabled";
			
			#address-cells = <1>;
			#size-cells = <0>;
			spidev@0x00 {
				compatible = "rohm,dh2228fv";
				spi-max-frequency = <20000000>;
				reg = <0>;
			};
		};
		
		ssp3: spi@56500000 {
			compatible = "faraday,ftssp010-spi";
			interrupt-parent = <&gic>;
			reg = <0x56500000 0x1000>;
			interrupts = <GIC_SPI 15 IRQ_TYPE_LEVEL_HIGH>;
			clocks = <&sspclk>;
			clock-names = "sspclk";
			pinctrl-0 = <&pinctrl_ftssp010_spi_3>;
			pinctrl-names = "sleep";
			dev_id = <3>;
			half-duplex;
			status = "disabled";
			
			#address-cells = <1>;
			#size-cells = <0>;
			spidev@0x00 {
				compatible = "rohm,dh2228fv";
				spi-max-frequency = <20000000>;
				reg = <0>;
			};
		};
		
		ssp4: spi@56600000 {
			compatible = "faraday,ftssp010-spi";
			interrupt-parent = <&gic>;
			reg = <0x56600000 0x1000>;
			interrupts = <GIC_SPI 16 IRQ_TYPE_LEVEL_HIGH>;
			clocks = <&sspclk>;
			clock-names = "sspclk";
			pinctrl-0 = <&pinctrl_ftssp010_spi_4>;
			pinctrl-names = "sleep";
			dev_id = <4>;  /*<2> spidev4.0*/
			status = "disabled";
			
			#address-cells = <1>;
			#size-cells = <0>;
			spidev@0x00 {
				compatible = "rohm,dh2228fv";
				spi-max-frequency = <20000000>;
				reg = <0>;
			};
		}; 
		
		ssp5: spi@56700000 {
			compatible = "faraday,ftssp010-spi";
			interrupt-parent = <&gic>;
			reg = <0x56700000 0x1000>;
			interrupts = <GIC_SPI 17 IRQ_TYPE_LEVEL_HIGH>;
			clocks = <&sspclk>;
			clock-names = "sspclk";
			pinctrl-0 = <&pinctrl_ftssp010_spi_5>;
			pinctrl-names = "default";
			dev_id = <5>;
			status = "disabled";
			
			#address-cells = <1>;
			#size-cells = <0>;
			spidev@0x00 {
				compatible = "rohm,dh2228fv";
				spi-max-frequency = <20000000>;
				reg = <0>;
			};
		};
		
		ssp6: spi@56800000 {
			compatible = "faraday,ftssp010-spi";
			interrupt-parent = <&gic>;
			reg = <0x56800000 0x1000>;
			interrupts = <GIC_SPI 18 IRQ_TYPE_LEVEL_HIGH>;
			clocks = <&sspclk>;
			clock-names = "sspclk";
			pinctrl-0 = <&pinctrl_ftssp010_spi_6>;
			pinctrl-names = "sleep";
			dev_id = <6>;
			status = "disabled";
			
			#address-cells = <1>;
			#size-cells = <0>;
			spidev@0x00 {
				compatible = "rohm,dh2228fv";
				spi-max-frequency = <20000000>;
				reg = <0>;
			};
		}; 
		
		ssp7: spi@22100000 {
			compatible = "faraday,ftssp010-spi";
			interrupt-parent = <&gic>;
			reg = <0x22100000 0x1000>;
			interrupts = <GIC_SPI 19 IRQ_TYPE_LEVEL_HIGH>;
			clocks = <&sspclk>;
			clock-names = "sspclk";
			dev_id = <7>;
			status = "disabled";
			
			#address-cells = <1>;
			#size-cells = <0>;
			spidev@0x00 {
				compatible = "rohm,dh2228fv";
				spi-max-frequency = <20000000>;
				reg = <0>;
			};
#if 0
			sc1168y@0x00 {
				compatible = "sc1168y";
				spi-max-frequency = <20000000>;
				spi-cpol;
				spi-cpha;
				reg = <0>;
			};
#endif
		}; 
		
		gmac0: gmac@541000000 {
			compatible = "faraday,ftgmac030";
			interrupt-parent = <&gic>;
			dev_id = <0>;
			reg = <0x54100000 0x1000>;
			clocks = <&gmacclk>;
			clock-names = "gmacclk";
			pinctrl-0 = <&pinctrl_ftgmac030_rgmii>;
			pinctrl-names = "default";
			interrupts = <GIC_SPI 7 IRQ_TYPE_LEVEL_HIGH>;
			status = "okay";
#if 0
     			fixed-link { 
           			speed = <1000>;
		  	        full-duplex;
		        };
#endif
		};
		
		gmac1: gmac@542000000 {
			compatible = "faraday,ftgmac030";
			interrupt-parent = <&gic>;
			dev_id = <0>;
			reg = <0x54200000 0x1000>;
			clocks = <&gmacclk>;
			clock-names = "gmacclk";
			pinctrl-0 = <&pinctrl_ftgmac030_rmii>;
                        pinctrl-names = "default";
			interrupts = <GIC_SPI 8 IRQ_TYPE_LEVEL_HIGH>;
			status = "okay";
			fixed-link { 
           			speed = <100>;
		  	        full-duplex;
		        };
		};
		
		gmac2: gmac@543000000 {
			compatible = "faraday,ftgmac030";
			interrupt-parent = <&gic>;
			dev_id = <1>;
			reg = <0x54300000 0x1000>;
			clocks = <&gmacclk>;
			clock-names = "gmacclk";
			pinctrl-0 = <&pinctrl_ftgmac030_mii>;
                        pinctrl-names = "default";
			interrupts = <GIC_SPI 9 IRQ_TYPE_LEVEL_HIGH>;
			status = "okay";
			fixed-link { 
           			speed = <100>;
		  	        full-duplex;
		        };
		};
		
		can0: can@56300000 {
			compatible = "faraday,ftcan010";
			interrupt-parent = <&gic>;
			reg = <0x56300000 0x1000>;
			interrupts = <GIC_SPI 70 IRQ_TYPE_LEVEL_HIGH>;
			clock-frequency = <100000000>;
			pinctrl-0 = <&pinctrl_ftcan010>;
			pinctrl-names = "default";
			status = "okay";
		};
		
		can1: can@54900000 {
			compatible = "faraday,ftcan010";
			interrupt-parent = <&gic>;
			reg = <0x54900000 0x1000>;
			interrupts = <GIC_SPI 71 IRQ_TYPE_LEVEL_HIGH>;
			clock-frequency = <100000000>; 
			pinctrl-0 = <&pinctrl_ftcan010_1>;
			pinctrl-names = "default";
			status = "okay";
		};
		
		usb0: usb_hcd@10200000 {
			compatible = "faraday,fotg210_hcd";
			interrupt-parent = <&gic>;
			reg = <0x10200000 0x1000>;
			interrupts = <GIC_SPI 81 IRQ_TYPE_LEVEL_HIGH>;
			mini-A-plug;
			status = "okay";
		};
		
		usb1: usb_udc@10200000 {
			compatible = "faraday,fotg210_udc";
			interrupt-parent = <&gic>;
			reg = <0x10200000 0x1000>;
			interrupts = <GIC_SPI 81 IRQ_TYPE_LEVEL_HIGH>;
			status = "disabled";
		};
		
		usb2: usb_hcd@10300000 {
			compatible = "faraday,fotg210_hcd";
			interrupt-parent = <&gic>;
			reg = <0x10300000 0x1000>;
			interrupts = <GIC_SPI 82 IRQ_TYPE_LEVEL_HIGH>;
			mini-A-plug;
			status = "okay";
		};
		
		usb3: usb_udc@10300000 {
			compatible = "faraday,fotg210_udc";
			interrupt-parent = <&gic>;
			reg = <0x10300000 0x1000>;
			interrupts = <GIC_SPI 82 IRQ_TYPE_LEVEL_HIGH>;
			status = "disabled";
		};
		
		usb4: usb_hcd@10400000 {
			compatible = "faraday,fotg210_hcd";
			interrupt-parent = <&gic>;
			reg = <0x10400000 0x1000>;
			interrupts = <GIC_SPI 83 IRQ_TYPE_LEVEL_HIGH>;
			mini-A-plug;
			status = "okay";
		};
		
		usb5: usb_udc@10400000 {
			compatible = "faraday,fotg210_udc";
			interrupt-parent = <&gic>;
			reg = <0x10400000 0x1000>;
			interrupts = <GIC_SPI 83 IRQ_TYPE_LEVEL_HIGH>;
			status = "disabled";
		};
		
		sd0: sd@12100000 {
			compatible = "faraday,ftsdc021-sdhci";
			interrupt-parent = <&gic>;
			reg = <0x12100000 0x1000>;
			clocks = <&sdclk>;
			clock-names = "sdclk";
			interrupts = <GIC_SPI 67 IRQ_TYPE_LEVEL_HIGH>;
			pulse-latch = <1>;
			bus-width = <4>;
			enable-8-bits;
			broken-cd;
			status = "okay";
		};
		
		sd1: sd@12200000 {
			compatible = "faraday,ftsdc021-sdhci";
			interrupt-parent = <&gic>;
			reg = <0x12200000 0x1000>;
			clocks = <&sdclk>;
			clock-names = "sdclk";
			pinctrl-0 = <&pinctrl_ftsdc021_emmc_1>;
			pinctrl-names = "default";
			interrupts = <GIC_SPI 68 IRQ_TYPE_LEVEL_HIGH>;
			pulse-latch = <1>;
			bus-width = <4>;
			enable-8-bits;
			broken-cd;
			status = "disabled";
		};
		
		cryptomaster0:cryptomaster@28300000 {
			compatible = "cryptomaster";
			interrupt-parent = <&gic>;
			reg = <0x28300000 0x100000>;
			interrupts = <GIC_SPI 95 IRQ_TYPE_LEVEL_HIGH>;
			status = "disabled";
		};
		
		trng0: trng@28400000 {
			compatible = "ba431trng";
			interrupt-parent = <&gic>;
			reg = <0x28400000 0x100>;
			interrupts = <GIC_SPI 94 IRQ_TYPE_LEVEL_HIGH>;
			status = "disabled";
		};
		
		pwm0: pwm@55300000 {
			compatible = "faraday,ftpwmtmr010-pwm";
			interrupt-parent = <&gic>;
			reg = <0x55300000 0x1000>;
			interrupts = <GIC_SPI 20 IRQ_TYPE_LEVEL_HIGH>;
			clocks = <&apb>;
			clock-names = "APB";
			pinctrl-0 = <&pinctrl_ftpwmtmr010>;
			pinctrl-names = "sleep";
			status = "disabled";
		};
		
		pwm1: pwm@55400000 {
			compatible = "faraday,ftpwmtmr010-pwm";
			interrupt-parent = <&gic>;
			reg = <0x55400000 0x1000>;
			interrupts = <GIC_SPI 25 IRQ_TYPE_LEVEL_HIGH>;
			clocks = <&apb>;
			clock-names = "APB";
			pinctrl-0 = <&pinctrl_ftpwmtmr010_1>;
			pinctrl-names = "sleep";
			status = "disabled";
		};
		
		pwm2: pwm@56d00000 {
			compatible = "faraday,ftpwmtmr010-pwm";
			interrupt-parent = <&gic>;
			reg = <0x56d00000 0x1000>;
			interrupts = <GIC_SPI 30 IRQ_TYPE_LEVEL_HIGH>;
			clocks = <&apb>;
			clock-names = "APB";
			pinctrl-0 = <&pinctrl_ftpwmtmr010_2>;
			pinctrl-names = "sleep";
			status = "disabled";
		};
		
		pwm3: pwm@56e00000 {
			compatible = "faraday,ftpwmtmr010-pwm";
			interrupt-parent = <&gic>;
			reg = <0x56e00000 0x1000>;
			interrupts = <GIC_SPI 35 IRQ_TYPE_LEVEL_HIGH>;
			clocks = <&apb>;
			clock-names = "APB";
			pinctrl-0 = <&pinctrl_ftpwmtmr010_3>;
			pinctrl-names = "sleep";
			status = "disabled";
		};
		
		i2c0: i2c@55500000 {
			compatible = "faraday,ftiic010";
			interrupt-parent = <&gic>;
			dev_id = <0>;
			reg = <0x55500000 0x1000>;
			interrupts = <GIC_SPI 40 IRQ_TYPE_LEVEL_HIGH>;
			clocks = <&pclk>;
			clock-names = "pclk";
			status = "disabled";
		};
		
		i2c1: i2c@55600000 {
			compatible = "faraday,ftiic010";
			interrupt-parent = <&gic>;
			#address-cells = <1>;
			#size-cells = <0>;
			dev_id = <1>;
			reg = <0x55600000 0x1000>;
			interrupts = <GIC_SPI 41 IRQ_TYPE_LEVEL_HIGH>;
			clocks = <&pclk>;
			clock-names = "pclk";
			status = "okay";
			at24c08@50{
				 compatible = "atmel,eeprom";
				 reg = <0x50>;
				 interrupts = <7 1>;
				 interrupts-parent = <&gic>;
			};
#if 0                     
			rtc@32 {
				compatible = "epson,rx8025";
				reg = <0x32>;
				second_interrput = <&gpio1 26 GPIO_ACTIVE_LOW>; 
			};
#endif
		};
		
		i2c2: i2c@55700000 {
			compatible = "faraday,ftiic010";
			interrupt-parent = <&gic>;
			#address-cells = <1>;
			#size-cells = <0>;
			dev_id = <2>;
			reg = <0x55700000 0x1000>;
			interrupts = <GIC_SPI 42 IRQ_TYPE_LEVEL_HIGH>;
			clocks = <&pclk>;
			clock-names = "pclk";
			status = "disabled";
#if 0
			wm8731: wm8731@1b {
				#sound-dai-cells = <0>;
				compatible = "wlf,wm8731";
				reg = <0x1b>;
			};
#endif
		};
		
		i2c3: i2c@56f00000 {
			compatible = "faraday,ftiic010";
			interrupt-parent = <&gic>;
			dev_id = <3>;
			reg = <0x56f00000 0x1000>;
			interrupts = <GIC_SPI 43 IRQ_TYPE_LEVEL_HIGH>;
			clocks = <&pclk>;
			clock-names = "pclk";
			status = "disabled";
		
		};
		
		i2c4: i2c@57000000 {
			compatible = "faraday,ftiic010";
			interrupt-parent = <&gic>;
			dev_id = <4>;
			reg = <0x57000000 0x1000>;
			interrupts = <GIC_SPI 44 IRQ_TYPE_LEVEL_HIGH>;
			clocks = <&pclk>;
			clock-names = "pclk";
			pinctrl-0 = <&pinctrl_ftiic010_4>;
			pinctrl-names = "default";
			status = "disabled";
		};
		
		gpio0: gpio@54000000 {
			compatible = "faraday,ftgpio010";
			interrupt-parent = <&gic>;
			gpio-controller;
			#gpio-cells = <2>;
			dev_id = <0>;
			reg = <0x54000000 0x1000>;
			interrupts = <GIC_SPI 1 IRQ_TYPE_LEVEL_HIGH>;
			pinctrl-0 = <&pinctrl_ftgpio010>;
			pinctrl-names = "default";
#if 0
			pin-mux-modex;
#endif
			status = "okay";
		};
		
		gpio1: gpio@56000000 {
			compatible = "faraday,ftgpio010";
			interrupt-parent = <&gic>;
			gpio-controller;
			#gpio-cells = <2>;
			dev_id = <1>;
			reg = <0x56000000 0x1000>;
			interrupts = <GIC_SPI 2 IRQ_TYPE_LEVEL_HIGH>;
			pinctrl-0 = <&pinctrl_ftgpio010_1>;
			pinctrl-names = "default";
			status = "okay";
		};
		
         	gpio_keys: gpio@0 {
			compatible = "smartchip,scm801-keypad";
			btn0{
                   	 	label = "key0";
                   	 	gpios = <&gpio0 22 GPIO_ACTIVE_LOW>;
                   	 	linux,code = <KEY_L>;
                  	 	//wakeup-source;
               		 };
           		btn1{
				label = "key1";
                   		gpios = <&gpio0 25 GPIO_ACTIVE_LOW>;
                    		linux,code = <KEY_S>;
                  		 //wakeup-source;
                	};

    		};	

		kbc0: kbc@56100000 {
			compatible = "faraday,ftkbc010";
			reg = <0x56100000 0x1000>;
			interrupts = <GIC_SPI 72 IRQ_TYPE_LEVEL_HIGH>;
			keypad,num-rows = <8>;
			keypad,num-columns = <8>;
			pinctrl-0 = <&pinctrl_ftkbc010>;
			pinctrl-names = "default";
			status = "disabled";
			
			linux,keymap = < MATRIX_KEY(0, 0, KEY_1)
			                 MATRIX_KEY(1, 0, KEY_2)
			                 MATRIX_KEY(2, 0, KEY_3)
			                 MATRIX_KEY(3, 0, KEY_4)
			                 MATRIX_KEY(4, 0, KEY_5)
			                 MATRIX_KEY(5, 0, KEY_6)
			                 MATRIX_KEY(6, 0, KEY_7)
			                 MATRIX_KEY(7, 0, KEY_8)
			                 MATRIX_KEY(0, 1, KEY_9)
			                 MATRIX_KEY(1, 1, KEY_A)
			                 MATRIX_KEY(2, 1, KEY_B)
			                 MATRIX_KEY(3, 1, KEY_C)
			                 MATRIX_KEY(4, 1, KEY_D)
			                 MATRIX_KEY(5, 1, KEY_E)
			                 MATRIX_KEY(6, 1, KEY_F)
			                 MATRIX_KEY(7, 1, KEY_G)
			                 MATRIX_KEY(0, 2, KEY_H)
			                 MATRIX_KEY(1, 2, KEY_I)
			                 MATRIX_KEY(2, 2, KEY_J)
			                 MATRIX_KEY(3, 2, KEY_K)
			                 MATRIX_KEY(4, 2, KEY_L)
			                 MATRIX_KEY(5, 2, KEY_M)
			                 MATRIX_KEY(6, 2, KEY_N)
			                 MATRIX_KEY(7, 2, KEY_O)
			                 MATRIX_KEY(0, 3, KEY_P)
			                 MATRIX_KEY(1, 3, KEY_Q)
			                 MATRIX_KEY(2, 3, KEY_R)
			                 MATRIX_KEY(3, 3, KEY_S)
			                 MATRIX_KEY(4, 3, KEY_T)
			                 MATRIX_KEY(5, 3, KEY_U)
			                 MATRIX_KEY(6, 3, KEY_V)
			                 MATRIX_KEY(7, 3, KEY_W)
			                 MATRIX_KEY(0, 4, KEY_X)
			                 MATRIX_KEY(1, 4, KEY_Y)
			                 MATRIX_KEY(2, 4, KEY_Z)
			                 MATRIX_KEY(3, 4, 51)
			                 MATRIX_KEY(4, 4, 52)
			                 MATRIX_KEY(5, 4, 53)
			                 MATRIX_KEY(6, 4, 54)
			                 MATRIX_KEY(7, 4, 55)
			                 MATRIX_KEY(0, 5, 56)
			                 MATRIX_KEY(1, 5, 57)
			                 MATRIX_KEY(2, 5, 58)
			                 MATRIX_KEY(3, 5, 59)
			                 MATRIX_KEY(4, 5, 60)
			                 MATRIX_KEY(5, 5, 61)
			                 MATRIX_KEY(6, 5, 62)
			                 MATRIX_KEY(7, 5, 63)
			                 MATRIX_KEY(0, 6, 64)
			                 MATRIX_KEY(1, 6, 65)
			                 MATRIX_KEY(2, 6, 66)
			                 MATRIX_KEY(3, 6, 67)
			                 MATRIX_KEY(4, 6, 68)
			                 MATRIX_KEY(5, 6, 69)
			                 MATRIX_KEY(6, 6, 70)
			                 MATRIX_KEY(7, 6, 71)
			                 MATRIX_KEY(0, 7, 72)
			                 MATRIX_KEY(1, 7, 73)
			                 MATRIX_KEY(2, 7, 74)
			                 MATRIX_KEY(3, 7, 75)
			                 MATRIX_KEY(4, 7, KEY_F1)
			                 MATRIX_KEY(5, 7, KEY_F2)
			                 MATRIX_KEY(6, 7, KEY_F3)
			                 MATRIX_KEY(7, 7, KEY_F4) >;
		};
		
		lcd0: lcd@56200000 {
			compatible = "faraday,ftlcdc210";
			interrupt-parent = <&gic>;
			reg = <0x56200000 0x10000>;
			interrupts = <GIC_SPI 84 IRQ_TYPE_LEVEL_HIGH>,
			             <GIC_SPI 85 IRQ_TYPE_LEVEL_HIGH>,
			             <GIC_SPI 86 IRQ_TYPE_LEVEL_HIGH>,
			             <GIC_SPI 87 IRQ_TYPE_LEVEL_HIGH>;
			clocks = <&lcclk>;
			clock-names = "lcclk";
			pinctrl-0 = <&pinctrl_ftlcdc210>;
			pinctrl-names = "default";
			dmas = <&dma0 0 0xFF 0>;
			dma-names = "imgblt";
			status = "disabled";
		};
		
		i2s0: i2s@54a00000 {
			compatible = "faraday,ftssp010-i2s";
			interrupt-parent = <&gic>;
			#sound-dai-cells = <0>;
			dmas = <&dma0 0 0xFF 12>, <&dma0 0 0xFF 13>;
			dma-names = "tx", "rx";
			reg = <0x54a00000 0x1000>;
			interrupts = <GIC_SPI 10 IRQ_TYPE_LEVEL_HIGH>;
			clocks = <&sspclk_i2s>;
			clock-names = "sspclk_i2s";
			pinctrl-0 = <&pinctrl_ftssp010_i2s>;
			pinctrl-names = "default";
			status = "disabled";
		};
		
		i2s1: i2s@56400000 {
			compatible = "faraday,ftssp010-i2s";
			interrupt-parent = <&gic>;
			#sound-dai-cells = <0>;
			dmas = <&dma0 0 0xFF 14>, <&dma0 0 0xFF 15>;
			dma-names = "tx", "rx";
			reg = <0x56400000 0x1000>;
			interrupts = <GIC_SPI 11 IRQ_TYPE_LEVEL_HIGH>;
			clocks = <&sspclk_i2s_1>;
			clock-names = "sspclk_i2s_1";
			pinctrl-0 = <&pinctrl_ftssp010_i2s_1>;
			pinctrl-names = "default";
			status = "disabled";
		};

#if 0
		sound0 {
			compatible = "simple-audio-card";
			simple-audio-card,name = "leo";
			simple-audio-card,format = "i2s";
			simple-audio-card,bitclock-master = <&sound0_cpu>;
			simple-audio-card,frame-master = <&sound0_cpu>;
			simple-audio-card,widgets = "Headphone", "Headphone Jack",
			                            "Speaker", "Ext Spk",
			                            "Microphone", "Microphone Jack",
			                            "Line", "Line In Jack";
			simple-audio-card,routing = "Headphone Jack", "LHPOUT",
			                            "Headphone Jack", "RHPOUT",
			                            "Ext Spk", "LOUT",
			                            "Ext Spk", "ROUT",
			                            "MICIN", "Microphone Jack",
			                            "LLINEIN", "Line In Jack",
			                            "RLINEIN", "Line In Jack";
			sound0_cpu: simple-audio-card,cpu {
				sound-dai = <&i2s0>;
			};
			sound0_codec: simple-audio-card,codec {
				sound-dai = <&wm8731>;
			};
		};
		
		sound1 {
			compatible = "simple-audio-card";
			simple-audio-card,name = "leo";
			simple-audio-card,format = "i2s";
			simple-audio-card,bitclock-master = <&sound1_cpu>;
			simple-audio-card,frame-master = <&sound1_cpu>;
			simple-audio-card,widgets = "Headphone", "Headphone Jack",
			                            "Speaker", "Ext Spk",
			                            "Microphone", "Microphone Jack",
			                            "Line", "Line In Jack";
			simple-audio-card,routing = "Headphone Jack", "LHPOUT",
			                            "Headphone Jack", "RHPOUT",
			                            "Ext Spk", "LOUT",
			                            "Ext Spk", "ROUT",
			                            "MICIN", "Microphone Jack",
			                            "LLINEIN", "Line In Jack",
			                            "RLINEIN", "Line In Jack";
			sound1_cpu: simple-audio-card,cpu {
				sound-dai = <&i2s1>;
			};
			sound1_codec: simple-audio-card,codec {
				sound-dai = <&wm8731>;
			};
		};
#endif
	};
};
